# Spirit3 register map
File version: 1.0
CPU: CM0+ r0p0, little endian, no MPU, no FPU, 2 interrupt priority bits
Registers are 32-bit, read-write, reset 0x0 unless marked. A register's access mark holds for its fields unless they carry their own. Offsets are from the block's base; [hi:lo] are bit positions; {n}, {i} and the like mark numbered series.

## PWR — Power control
Base 0x48500000
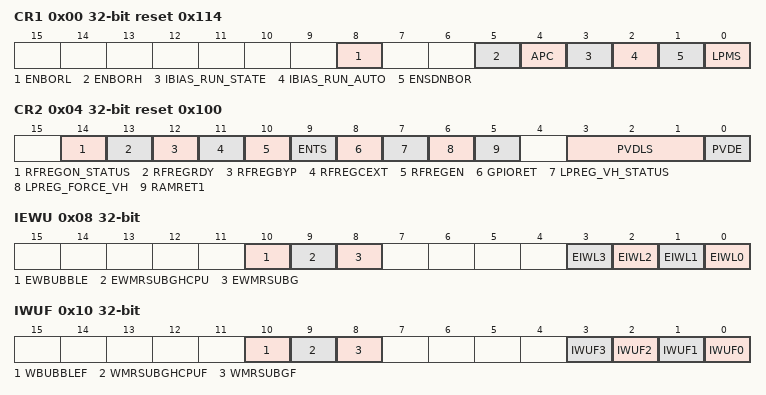
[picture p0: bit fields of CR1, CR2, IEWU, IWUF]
0x00 CR1 reset 0x114 — Power control register 1
  [8] ENBORL — Enable BORL reset supervising during RUN mode
  [5] ENBORH — Enable the BORH software configuration
  [4] APC — Apply pull-up/-down configuration from PWRC or GPIO register
  [3] IBIAS_RUN_STATE — Enable/Disable IBIAs during RUN mode when automatic mode is
  [2] IBIAS_RUN_AUTO — Enable automatic IBIAs control during RUN/DEEPSTOP mode
  [1] ENSDNBOR — Enable BOR reset supervising during SHUTDOWN mode
  [0] LPMS — Low Power Mode Selection
0x04 CR2 reset 0x100 — Power control register 2
  [14] RFREGON_STATUS — RF Regulator On Status
  [13] RFREGRDY — RF Regulator Ready flag
  [12] RFREGBYP — RF Regulator Bypass Enable
  [11] RFREGCEXT — RF Regulator External Supply Bypass
  [10] RFREGEN — RF Regulator enable
  [9] ENTS — Enable Temperature Sensor
  [8] GPIORET — GPIO retention enable
  [7] LPREG_VH_STATUS — LPREG status
  [6] LPREG_FORCE_VH — force LPREG=1.2V during DEEPSTOP mode
  [5] RAMRET1 — RAM1 retention during low power mode
  [3:1] PVDLS — Programmable Voltage Detector Level selection
  [0] PVDE — Programmable Voltage Detector Enable
0x08 IEWU — This register manages the selection of the internal wakeup sources to get out of DEEPSTOP mode
  [10] EWBUBBLE — Enable wakeup on Bubble RFIP event
  [9] EWMRSUBGHCPU — Enable wakeup on MRSUBG Host CPU event
  [8] EWMRSUBG — Enable wakeup on MRSUBG RFIP event
  [3] EIWL3 — Enable wakeup on Internal event (COMP)
  [2] EIWL2 — Enable wakeup on Internal event (LCD)
  [1] EIWL1 — Enable wakeup on Internal event (RTC)
  [0] EIWL0 — Enable wakeup on Internal event (LPUART)
0x0C IWUP — This register manages the polarity for the internal wakeup sources to get out of DEEPSTOP mode
  [3] IWUP3 — Wakeup polarity for internal wakeup line 3 event (COMP)
0x10 IWUF — This register provides the information concerning which internal source woke up the device after a DEEPSTOP
  [10] WBUBBLEF — Bubble RFIP wakeup flag
  [9] WMRSUBGHCPUF — MRSUBG Host CPU wakeup flag
  [8] WMRSUBGF — MRSUBG wakeup flag
  [3] IWUF3 — Internal wakeup flag (COMP)
  [2] IWUF2 — Internal wakeup flag (LCD)
  [1] IWUF1 — Internal wakeup flag (RTC)
  [0] IWUF0 — Internal wakeup flag (LPUART)
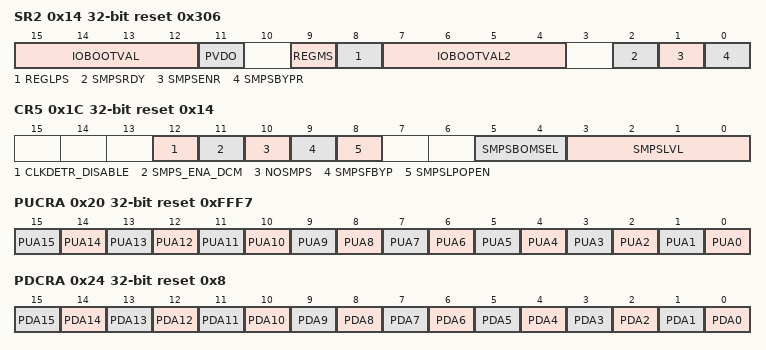
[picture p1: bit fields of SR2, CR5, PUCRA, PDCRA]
0x14 SR2 ro reset 0x306 — Power status register 2
  [15:12] IOBOOTVAL
  [11] PVDO — Power Voltage Detector Output
  [9] REGMS — Main regulator ready status
  [8] REGLPS — Regulator Low Power Started
  [7:4] IOBOOTVAL2 — I/Os value latched at POR
  [2] SMPSRDY — SMPs Ready Status
  [1] SMPSENR — SMPs Enable Control Replica
  [0] SMPSBYPR — SMPs Force Bypass Control Replica
0x1C CR5 reset 0x14 — Power control register 5
  [12] CLKDETR_DISABLE — disable the SMPs clock detection
  [11] SMPS_ENA_DCM — Discontinuous conduction mode enable
  [10] NOSMPS — No SMPs Mode
  [9] SMPSFBYP — Force SMPs Regulator in bypass mode
  [8] SMPSLPOPEN — In Low Power mode SMPs is in OPEN mode (instead of PRECHARGE mode)
  [5:4] SMPSBOMSEL — SMPs BOM Selection
  [3:0] SMPSLVL — SMPs Output Level Voltage Selection
0x20 PUCRA reset 0xFFF7 — Power Port A pull-up control register
  [n] PUA{n} (n=0..15) — Port A PAll-up bit {n}
0x24 PDCRA reset 0x8 — Power Port A pull-down control register
  [n] PDA{n} (n=0..15) — Port A pull-down bit {n}
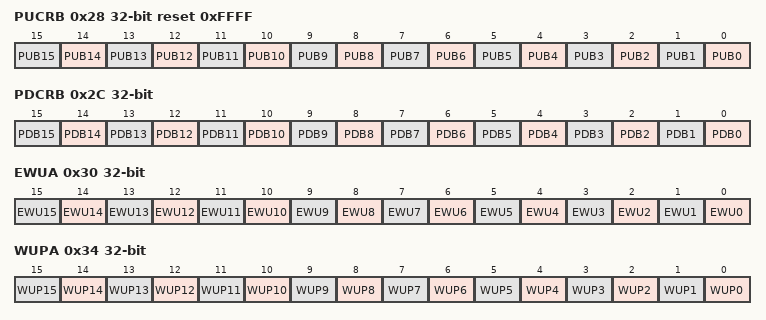
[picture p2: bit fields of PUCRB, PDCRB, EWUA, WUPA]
0x28 PUCRB reset 0xFFFF — Power Port B pull-up control register
  [n] PUB{n} (n=0..15) — Port B PBll-up bit {n}
0x2C PDCRB — Power Port B pull-down control register
  [n] PDB{n} (n=0..15) — Port B pull-down bit {n}
0x30 EWUA — This register manages the selection of the wakeup sources related to IO port A to get out of DEEPSTOP mode
  [n] EWU{n} (n=0..15) — Enable wakeup on PA{n} I/O event
0x34 WUPA — This register manages the polarity for the port A I/Os wakeup sources to get out of DEEPSTOP mode
  [n] WUP{n} (n=0..15) — Wakeup polarity for PA{n} I/O event
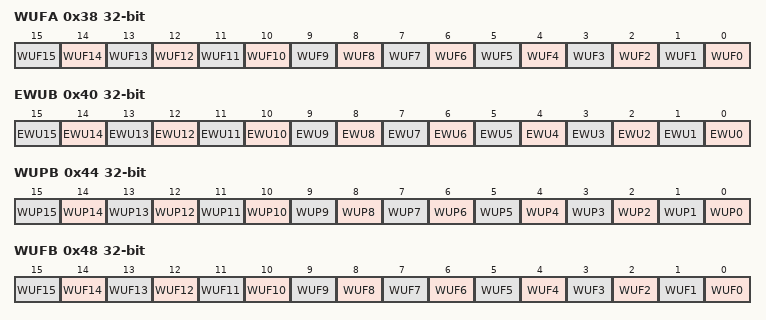
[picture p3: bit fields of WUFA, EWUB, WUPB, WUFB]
0x38 WUFA — This register provides the information concerning which port A I/O source woke up the device after a DEEPSTOP
  [n] WUF{n} (n=0..15) — PA{n} I/O wakeup flag
0x40 EWUB — This register manages the selection of the wakeup sources related to IO port B to get out of DEEPSTOP mode
  [n] EWU{n} (n=0..15) — Enable wakeup on PB{n} I/O event
0x44 WUPB — This register manages the polarity for the port B I/Os wakeup sources to get out of DEEPSTOP mode
  [n] WUP{n} (n=0..15) — Wakeup polarity for PB{n} I/O event
0x48 WUFB — This register provides the information concerning which port B I/O source woke up the device after a DEEPSTOP
  [n] WUF{n} (n=0..15) — PB{n} I/O wakeup flag
0x84 DBGR — This register is used for debug features
  [0] DEEPSTOP2 — DEEPSTOP2 low power saving emulation enable
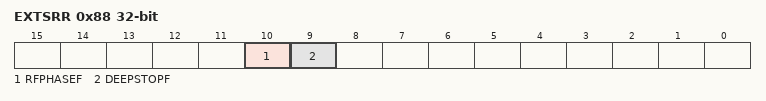
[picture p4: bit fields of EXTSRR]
0x88 EXTSRR — Power status clear register
  [10] RFPHASEF — RFPHAs Flag
  [9] DEEPSTOPF — System DeepStop Flag
